VERSION "HIPBNYYYYYYYYYYYYYYYYYYYYYYYYYYYYYYYYYYYYY/4/%%%/4/'%**4YYY///"

NS_ :

BS_:

BU_:

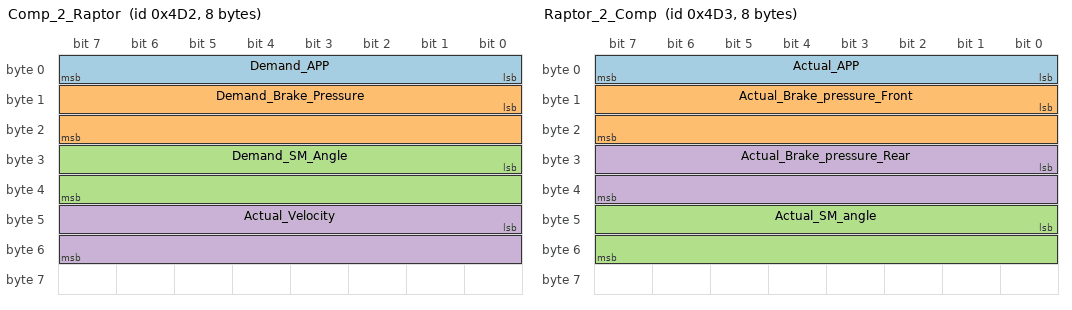
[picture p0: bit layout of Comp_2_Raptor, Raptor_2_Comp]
BO_ 1234 Comp_2_Raptor: 8 Vector__XXX
 SG_ Demand_APP : 0|8@1+ (0.5,0) [0|90] "" Vector__XXX
 SG_ Demand_Brake_Pressure : 8|16@1+ (6894,0) [0|2068200] "" Vector__XXX
 SG_ Demand_SM_Angle : 24|16@1+ (0.1,-195) [-195|195] "" Vector__XXX
 SG_ Actual_Velocity : 40|16@1+ (1,0) [0|400] "" Vector__XXX

BO_ 1235 Raptor_2_Comp: 8 Vector__XXX
 SG_ Actual_APP : 0|8@1+ (0.5,0) [0|90] "" Vector__XXX
 SG_ Actual_Brake_pressure_Front : 8|16@1+ (6894,0) [0|2757600] "" Vector__XXX
 SG_ Actual_SM_angle : 40|16@1+ (0.1,-195) [-195|195] "" Vector__XXX
 SG_ Actual_Brake_pressure_Rear : 24|16@1+ (6894,0) [0|2757600] "" Vector__XXX
